# AST1080 register map
File version: 1.0
CPU: CM4 r0p1, little endian, MPU, FPU, 4 interrupt priority bits, 256 interrupts
Registers are 32-bit, read-write, reset 0x0 unless marked. A register's access mark holds for its fields unless they carry their own. Offsets are from the block's base; [hi:lo] are bit positions; {n}, {i} and the like mark numbered series.

## wdt
Base 0x74C03000
Same registers: wdt1 0x74C03080, wdt2 0x74C03100, wdt3 0x74C03180, wdt4 0x74C03200, wdt5 0x74C03280, wdt6 0x74C03300, wdt7 0x74C03380
0x00 WDT000 reset 0x14FB180 — WDTn Counter Status Register
  [31:0] CounterSts ro — Counter status
0x04 WDT004 reset 0x14FB180 — WDTn Counter Reload Value Register
  [31:0] CounterReloadValueReg — Counter reload value register
0x08 WDT008 — WDTn Counter Restart Register
  [15:0] RestartReg — Restart register
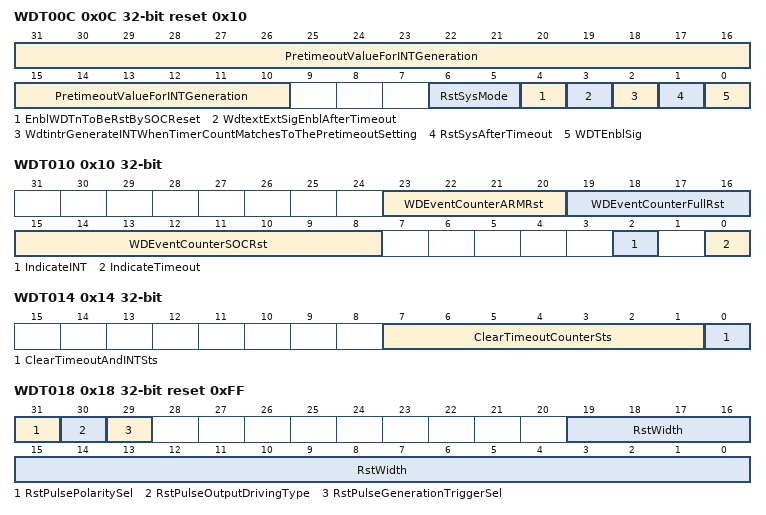
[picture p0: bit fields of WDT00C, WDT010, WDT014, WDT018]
0x0C WDT00C reset 0x10 — WDTn Control Register
  [31:10] PretimeoutValueForINTGeneration — Pre-timeout value for interrupt generation
  [6:5] RstSysMode — Reset system mode
    0=SOC_System_Ewvergated_By_Reset_Mask_Registers; 1=Full_Chip; 0b1x=CPUFMC_Only_Just_Reboot_Firmware_No_Any_Other_IPs_Will_Be_Reset
  [4] EnblWDTnToBeRstBySOCReset — Enable WDT(n) to be reset by SOC reset
    0=WDTn_Can_Not_Be_Reset_By_SOC_Reset_Only_SRST_Or_Full_Chip_Reset_Can_Reset_It; 1=WDTn_Can_Be_Reset_By_SOC_Reset
  [3] WdtextExtSigEnblAfterTimeout — wdt_ext: External signal enable after timeout
    0=Disable; 1=Enable
  [2] WdtintrGenerateINTWhenTimerCountMatchesToThePretimeoutSetting — wdt_intr: Generate interrupt when timer count matches to the pre-timeout setting
    0=Disable; 1=Enable
  [1] RstSysAfterTimeout — Reset system after timeout
    0=Disable; 1=Enable
  [0] WDTEnblSig — WDT enable signal
    0=Disable; 1=Enable
0x10 WDT010 — WDTn Timeout Status Register
  [23:20] WDEventCounterARMRst ro — Watchdog event counter : ARM reset
  [19:16] WDEventCounterFullRst ro — Watchdog event counter : Full reset
  [15:8] WDEventCounterSOCRst ro — Watchdog event counter : SOC reset
  [2] IndicateINT ro — Indicate interrupt
  [0] IndicateTimeout ro
    0=Timeout_Never_Occur; 1=Timeout_Occur
0x14 WDT014 — WDTn Clear Timeout Status Register
  [7:1] ClearTimeoutCounterSts — Clear timeout counter status
  [0] ClearTimeoutAndINTSts — Clear timeout and interrupt status
0x18 WDT018 reset 0xFF — WDTn Reset Width Register
  [31] RstPulsePolaritySel — Reset pulse polarity selection
    0=Active_Low_Output; 1=Active_High_Output
  [30] RstPulseOutputDrivingType — Reset pulse output driving type
    0=Opendrain; 1=Pushpull
  [29] RstPulseGenerationTriggerSel — Reset pulse generation trigger selection
    0=Trigger_By_Timeout; 1=Trigger_By_Pretimeout
  [19:0] RstWidth — Reset width
0x24 WDT024 reset 0x3FFFFF1 (reset mask 0xFF6D01) — WDTn Reset Mask Register \#1
  [n+16] EnblRstI3CBus{n}Ctrl (n=0..7) — Enable reset I3C bus{n} controller
  [14] EnblRstSPI1Ctrl — Enable reset SPI1 controller
  [13] EnblRstSPI0Ctrl — Enable reset SPI0 controller
  [12] EnblRstJTAGMaster1Ctrl — Enable reset JTAG Master #1 controller
  [11] EnblRstJTAGMaster0Ctrl — Enable reset JTAG Master #0 controller
  [11] EnblRstJTAGMasterCtrl — Enable reset JTAG Master controller
  [10] EnblRstESPICtrl — Enable reset eSPI controller
  [10] EnblRstESPICtrl1 — Enable reset eSPI controller
  [8] EnblRstADCCtrl — Enable reset ADC controller
  [4] EnblRstPWMCtrl — Enable reset PWM controller
  [3] EnblRstPECIBridge — Enable reset PECI bridge
  [0] EnblRstLSCRelatedCtrls — Enable reset LSC related controllers
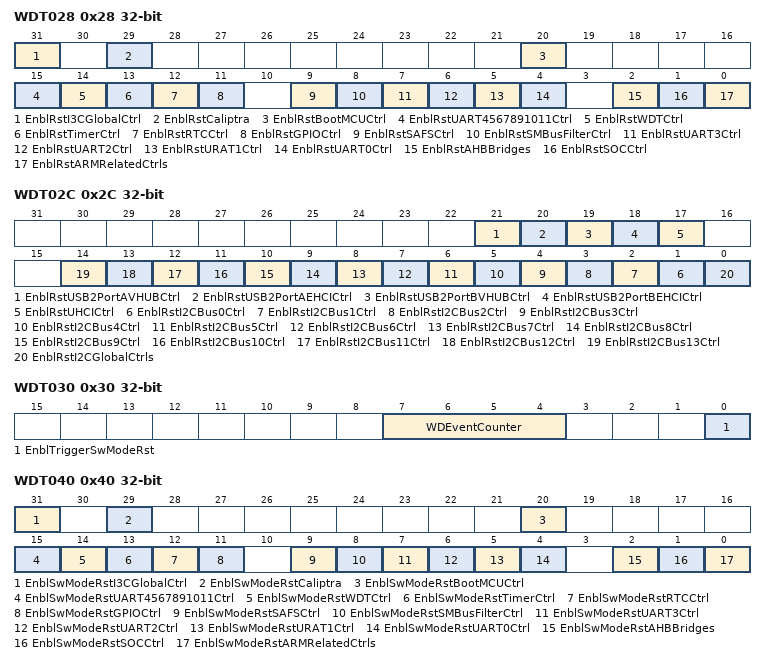
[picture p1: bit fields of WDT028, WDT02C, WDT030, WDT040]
0x28 WDT028 (reset mask 0xA010F8F7) — WDTn Reset Mask Register \#2
  [31] EnblRstI3CGlobalCtrl — Enable reset I3C global controller
  [29] EnblRstCaliptra — Enable reset Caliptra
  [20] EnblRstBootMCUCtrl — Enable reset BootMCU controller
  [15] EnblRstUART4567891011Ctrl — Enable reset UART #4/#5/#6/#7/#8/#9/#10/#11 controller
  [14] EnblRstWDTCtrl — Enable reset WDT controller
  [13] EnblRstTimerCtrl — Enable reset Timer controller
  [12] EnblRstRTCCtrl — Enable reset RTC controller
  [11] EnblRstGPIOCtrl — Enable reset GPIO controller
  [9] EnblRstSAFSCtrl — Enable reset SAFS controller
  [8] EnblRstSMBusFilterCtrl — Enable reset SMBus Filter controller
  [7] EnblRstUART3Ctrl — Enable reset UART #3 controller
  [6] EnblRstUART2Ctrl — Enable reset UART #2 controller
  [5] EnblRstURAT1Ctrl — Enable reset URAT #1 controller
  [4] EnblRstUART0Ctrl — Enable reset UART #0 controller
  [2] EnblRstAHBBridges — Enable reset AHB bridges
  [1] EnblRstSOCCtrl — Enable reset SOC controller
  [0] EnblRstARMRelatedCtrls — Enable reset ARM related controllers
0x2C WDT02C — WDTn Reset Mask Register \#3
  [21] EnblRstUSB2PortAVHUBCtrl — Enable reset USB2 PortA vHUB controller
  [20] EnblRstUSB2PortAEHCICtrl — Enable reset USB2 PortA EHCI controller
  [19] EnblRstUSB2PortBVHUBCtrl — Enable reset USB2 PortB vHUB controller
  [18] EnblRstUSB2PortBEHCICtrl — Enable reset USB2 PortB EHCI controller
  [17] EnblRstUHCICtrl — Enable reset UHCI controller
  [n+1] EnblRstI2CBus{n}Ctrl (n=0..13) — Enable reset I2C bus{n} controller
  [0] EnblRstI2CGlobalCtrls — Enable reset I2C global controllers
0x30 WDT030 — WDTn Software Mode Reset Control Register
  [7:4] WDEventCounter — Watchdog event counter
  [0] EnblTriggerSwModeRst — Enable trigger software mode reset
0x3C WDT03C reset 0x3FFFFF1 (reset mask 0xFF6D01) — WDTn Software Mode Reset Mask Register \#1
  [n+16] EnblSwModeRstI3CBus{n}Ctrl (n=0..7) — Enable Software Mode reset I3C bus{n} controller
  [14] EnblSwModeRstSPI1Ctrl — Enable Software Mode reset SPI1 controller
  [13] EnblSwModeRstSPI0Ctrl — Enable Software Mode reset SPI0 controller
  [12] EnblSwModeRstJTAGMaster1Ctrl — Enable Software Mode reset JTAG Master #1 controller
  [11] EnblSwModeRstJTAGMaster0Ctrl — Enable Software Mode reset JTAG Master #0 controller
  [11] EnblSwModeRstJTAGMasterCtrl — Enable Software Mode reset JTAG Master controller
  [10] EnblSwModeRstESPICtrl — Enable Software Mode reset eSPI controller
  [10] EnblSwModeRstESPICtrl1 — Enable Software Mode reset eSPI controller
  [8] EnblSwModeRstADCCtrl — Enable Software Mode reset ADC controller
  [4] EnblSwModeRstPWMCtrl — Enable Software Mode reset PWM controller
  [3] EnblSwModeRstPECIBridge — Enable Software Mode reset PECI bridge
  [0] EnblSwModeRstLSCRelatedCtrls — Enable Software Mode reset LSC related controllers
0x40 WDT040 (reset mask 0xA010F8F7) — WDTn Software Mode Reset Mask Register \#2
  [31] EnblSwModeRstI3CGlobalCtrl — Enable Software Mode reset I3C global controller
  [29] EnblSwModeRstCaliptra — Enable Software Mode reset Caliptra
  [20] EnblSwModeRstBootMCUCtrl — Enable Software Mode reset BootMCU controller
  [15] EnblSwModeRstUART4567891011Ctrl — Enable Software Mode reset UART #4/#5/#6/#7/#8/#9/#10/#11 controller
  [14] EnblSwModeRstWDTCtrl — Enable Software Mode reset WDT controller
  [13] EnblSwModeRstTimerCtrl — Enable Software Mode reset Timer controller
  [12] EnblSwModeRstRTCCtrl — Enable Software Mode reset RTC controller
  [11] EnblSwModeRstGPIOCtrl — Enable Software Mode reset GPIO controller
  [9] EnblSwModeRstSAFSCtrl — Enable Software Mode reset SAFS controller
  [8] EnblSwModeRstSMBusFilterCtrl — Enable Software Mode reset SMBus Filter controller
  [7] EnblSwModeRstUART3Ctrl — Enable Software Mode reset UART #3 controller
  [6] EnblSwModeRstUART2Ctrl — Enable Software Mode reset UART #2 controller
  [5] EnblSwModeRstURAT1Ctrl — Enable Software Mode reset URAT #1 controller
  [4] EnblSwModeRstUART0Ctrl — Enable Software Mode reset UART #0 controller
  [2] EnblSwModeRstAHBBridges — Enable Software Mode reset AHB bridges
  [1] EnblSwModeRstSOCCtrl — Enable Software Mode reset SOC controller
  [0] EnblSwModeRstARMRelatedCtrls — Enable Software Mode reset ARM related controllers
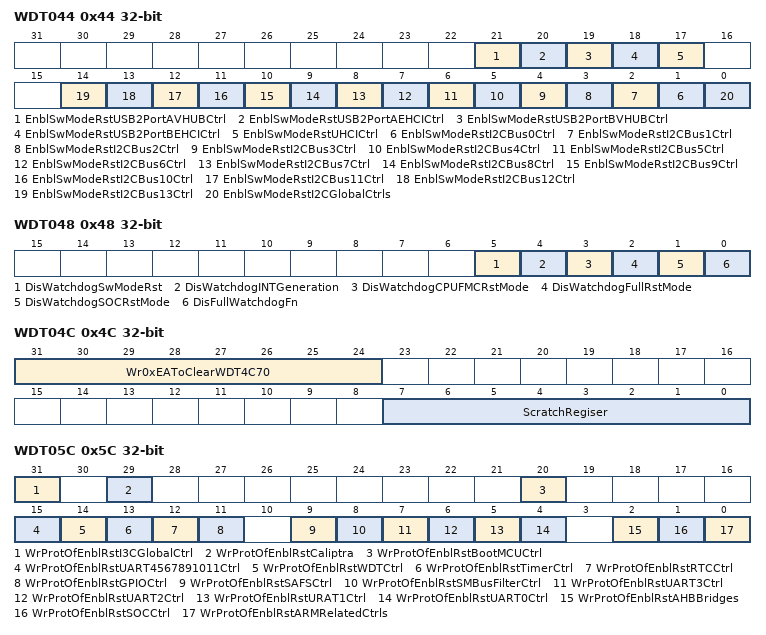
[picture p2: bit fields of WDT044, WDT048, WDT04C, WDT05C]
0x44 WDT044 — WDTn Software Mode Reset Mask Register \#3
  [21] EnblSwModeRstUSB2PortAVHUBCtrl — Enable Software Mode reset USB2 PortA vHUB controller
  [20] EnblSwModeRstUSB2PortAEHCICtrl — Enable Software Mode reset USB2 PortA EHCI controller
  [19] EnblSwModeRstUSB2PortBVHUBCtrl — Enable Software Mode reset USB2 PortB vHUB controller
  [18] EnblSwModeRstUSB2PortBEHCICtrl — Enable Software Mode reset USB2 PortB EHCI controller
  [17] EnblSwModeRstUHCICtrl — Enable Software Mode reset UHCI controller
  [n+1] EnblSwModeRstI2CBus{n}Ctrl (n=0..13) — Enable Software Mode reset I2C bus{n} controller
  [0] EnblSwModeRstI2CGlobalCtrls — Enable Software Mode reset I2C global controllers
0x48 WDT048 — WDTn Funtion Disable Control Register
  [5] DisWatchdogSwModeRst — Disable watchdog Software mode reset
  [4] DisWatchdogINTGeneration — Disable watchdog interrupt generation
  [3] DisWatchdogCPUFMCRstMode — Disable watchdog CPU/FMC reset mode
  [2] DisWatchdogFullRstMode — Disable watchdog Full reset mode
  [1] DisWatchdogSOCRstMode — Disable watchdog SOC reset mode
  [0] DisFullWatchdogFn — Disable full watchdog function
0x4C WDT04C — WDTn Scratch Register
  [31:24] Wr0xEAToClearWDT4C70 — Write 0xEA to clear WDT4C[7:0]
  [7:0] ScratchRegiser
0x58 WDT058 reset 0x3FFFFF1 (reset mask 0xFF6D01) — WDTn Reset Mask Write Protection Register \#1
  [n+16] WrProtOfEnblRstI3CBus{n}Ctrl (n=0..7) — Write Protection of Enable reset I3C bus{n} controller
  [14] WrProtOfEnblRstSPI1Ctrl — Write Protection of Enable reset SPI1 controller
  [13] WrProtOfEnblRstSPI0Ctrl — Write Protection of Enable reset SPI0 controller
  [12] WrProtOfEnblRstJTAGMaster1Ctrl — Write Protection of Enable reset JTAG Master #1 controller
  [11] WrProtOfEnblRstJTAGMaster0Ctrl — Write Protection of Enable reset JTAG Master #0 controller
  [11] WrProtOfEnblRstJTAGMasterCtrl — Write Protection of Enable reset JTAG Master controller
  [10] WrProtOfEnblRstESPICtrl — Write Protection of Enable reset eSPI controller
  [10] WrProtOfEnblRstESPICtrl1 — Write Protection of Enable reset eSPI controller
  [8] WrProtOfEnblRstADCCtrl — Write Protection of Enable reset ADC controller
  [4] WrProtOfEnblRstPWMCtrl — Write Protection of Enable reset PWM controller
  [3] WrProtOfEnblRstPECIBridge — Write Protection of Enable reset PECI bridge
  [0] WrProtOfEnblRstLSCRelatedCtrls — Write Protection of Enable reset LSC related controllers
0x5C WDT05C (reset mask 0xA010F8F7) — WDTn Reset Mask Write Protection Register \#2
  [31] WrProtOfEnblRstI3CGlobalCtrl — Write Protection of Enable reset I3C global controller
  [29] WrProtOfEnblRstCaliptra — Write Protection of Enable reset Caliptra
  [20] WrProtOfEnblRstBootMCUCtrl — Write Protection of Enable reset BootMCU controller
  [15] WrProtOfEnblRstUART4567891011Ctrl — Write Protection of Enable reset UART #4/#5/#6/#7/#8/#9/#10/#11 controller
  [14] WrProtOfEnblRstWDTCtrl — Write Protection of Enable reset WDT controller
  [13] WrProtOfEnblRstTimerCtrl — Write Protection of Enable reset Timer controller
  [12] WrProtOfEnblRstRTCCtrl — Write Protection of Enable reset RTC controller
  [11] WrProtOfEnblRstGPIOCtrl — Write Protection of Enable reset GPIO controller
  [9] WrProtOfEnblRstSAFSCtrl — Write Protection of Enable reset SAFS controller
  [8] WrProtOfEnblRstSMBusFilterCtrl — Write Protection of Enable reset SMBus Filter controller
  [7] WrProtOfEnblRstUART3Ctrl — Write Protection of Enable reset UART #3 controller
  [6] WrProtOfEnblRstUART2Ctrl — Write Protection of Enable reset UART #2 controller
  [5] WrProtOfEnblRstURAT1Ctrl — Write Protection of Enable reset URAT #1 controller
  [4] WrProtOfEnblRstUART0Ctrl — Write Protection of Enable reset UART #0 controller
  [2] WrProtOfEnblRstAHBBridges — Write Protection of Enable reset AHB bridges
  [1] WrProtOfEnblRstSOCCtrl — Write Protection of Enable reset SOC controller
  [0] WrProtOfEnblRstARMRelatedCtrls — Write Protection of Enable reset ARM related controllers
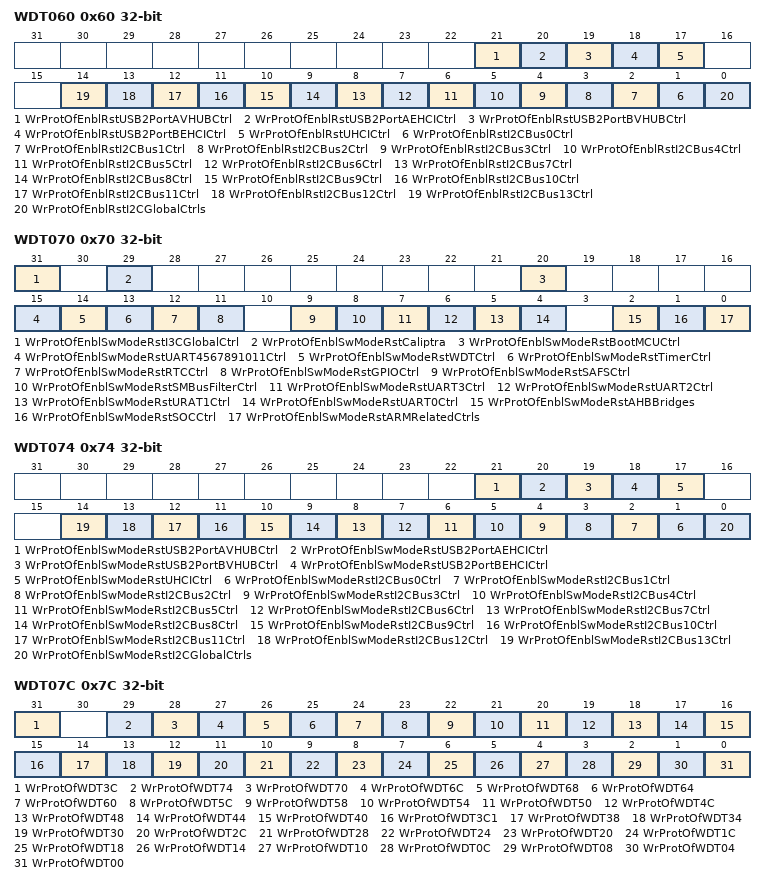
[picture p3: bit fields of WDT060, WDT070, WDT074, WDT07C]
0x60 WDT060 — WDTn Reset Mask Write Protection Register \#3
  [21] WrProtOfEnblRstUSB2PortAVHUBCtrl — Write Protection of Enable reset USB2 PortA vHUB controller
  [20] WrProtOfEnblRstUSB2PortAEHCICtrl — Write Protection of Enable reset USB2 PortA EHCI controller
  [19] WrProtOfEnblRstUSB2PortBVHUBCtrl — Write Protection of Enable reset USB2 PortB vHUB controller
  [18] WrProtOfEnblRstUSB2PortBEHCICtrl — Write Protection of Enable reset USB2 PortB EHCI controller
  [17] WrProtOfEnblRstUHCICtrl — Write Protection of Enable reset UHCI controller
  [n+1] WrProtOfEnblRstI2CBus{n}Ctrl (n=0..13) — Write Protection of Enable reset I2C bus{n} controller
  [0] WrProtOfEnblRstI2CGlobalCtrls — Write Protection of Enable reset I2C global controllers
0x6C WDT06C reset 0x3FFFFF1 (reset mask 0xFF6D01) — WDTn Reset Mask Write Protection Register \#1
  [n+16] WrProtOfEnblSwModeRstI3CBus{n}Ctrl (n=0..7) — Write Protection of Enable Software Mode reset I3C bus{n} controller
  [14] WrProtOfEnblSwModeRstSPI1Ctrl — Write Protection of Enable Software Mode reset SPI1 controller
  [13] WrProtOfEnblSwModeRstSPI0Ctrl — Write Protection of Enable Software Mode reset SPI0 controller
  [12] WrProtOfEnblSwModeRstJTAGMaster1Ctrl — Write Protection of Enable Software Mode reset JTAG Master #1 controller
  [11] WrProtOfEnblSwModeRstJTAGMaster0Ctrl — Write Protection of Enable Software Mode reset JTAG Master #0 controller
  [11] WrProtOfEnblSwModeRstJTAGMasterCtrl — Write Protection of Enable Software Mode reset JTAG Master controller
  [10] WrProtOfEnblSwModeRstESPICtrl — Write Protection of Enable Software Mode reset eSPI controller
  [10] WrProtOfEnblSwModeRstESPICtrl1 — Write Protection of Enable Software Mode reset eSPI controller
  [8] WrProtOfEnblSwModeRstADCCtrl — Write Protection of Enable Software Mode reset ADC controller
  [4] WrProtOfEnblSwModeRstPWMCtrl — Write Protection of Enable Software Mode reset PWM controller
  [3] WrProtOfEnblSwModeRstPECIBridge — Write Protection of Enable Software Mode reset PECI bridge
  [0] WrProtOfEnblSwModeRstLSCRelatedCtrls — Write Protection of Enable Software Mode reset LSC related controllers
0x70 WDT070 (reset mask 0xA010F8F7) — WDTn Reset Mask Write Protection Register \#2
  [31] WrProtOfEnblSwModeRstI3CGlobalCtrl — Write Protection of Enable Software Mode reset I3C global controller
  [29] WrProtOfEnblSwModeRstCaliptra — Write Protection of Enable Software Mode reset Caliptra
  [20] WrProtOfEnblSwModeRstBootMCUCtrl — Write Protection of Enable Software Mode reset BootMCU controller
  [15] WrProtOfEnblSwModeRstUART4567891011Ctrl — Write Protection of Enable Software Mode reset UART #4/#5/#6/#7/#8/#9/#10/#11 controller
  [14] WrProtOfEnblSwModeRstWDTCtrl — Write Protection of Enable Software Mode reset WDT controller
  [13] WrProtOfEnblSwModeRstTimerCtrl — Write Protection of Enable Software Mode reset Timer controller
  [12] WrProtOfEnblSwModeRstRTCCtrl — Write Protection of Enable Software Mode reset RTC controller
  [11] WrProtOfEnblSwModeRstGPIOCtrl — Write Protection of Enable Software Mode reset GPIO controller
  [9] WrProtOfEnblSwModeRstSAFSCtrl — Write Protection of Enable Software Mode reset SAFS controller
  [8] WrProtOfEnblSwModeRstSMBusFilterCtrl — Write Protection of Enable Software Mode reset SMBus Filter controller
  [7] WrProtOfEnblSwModeRstUART3Ctrl — Write Protection of Enable Software Mode reset UART #3 controller
  [6] WrProtOfEnblSwModeRstUART2Ctrl — Write Protection of Enable Software Mode reset UART #2 controller
  [5] WrProtOfEnblSwModeRstURAT1Ctrl — Write Protection of Enable Software Mode reset URAT #1 controller
  [4] WrProtOfEnblSwModeRstUART0Ctrl — Write Protection of Enable Software Mode reset UART #0 controller
  [2] WrProtOfEnblSwModeRstAHBBridges — Write Protection of Enable Software Mode reset AHB bridges
  [1] WrProtOfEnblSwModeRstSOCCtrl — Write Protection of Enable Software Mode reset SOC controller
  [0] WrProtOfEnblSwModeRstARMRelatedCtrls — Write Protection of Enable Software Mode reset ARM related controllers
0x74 WDT074 — WDTn Reset Mask Write Protection Register \#3
  [21] WrProtOfEnblSwModeRstUSB2PortAVHUBCtrl — Write Protection of Enable Software Mode reset USB2 PortA vHUB controller
  [20] WrProtOfEnblSwModeRstUSB2PortAEHCICtrl — Write Protection of Enable Software Mode reset USB2 PortA EHCI controller
  [19] WrProtOfEnblSwModeRstUSB2PortBVHUBCtrl — Write Protection of Enable Software Mode reset USB2 PortB vHUB controller
  [18] WrProtOfEnblSwModeRstUSB2PortBEHCICtrl — Write Protection of Enable Software Mode reset USB2 PortB EHCI controller
  [17] WrProtOfEnblSwModeRstUHCICtrl — Write Protection of Enable Software Mode reset UHCI controller
  [n+1] WrProtOfEnblSwModeRstI2CBus{n}Ctrl (n=0..13) — Write Protection of Enable Software Mode reset I2C bus{n} controller
  [0] WrProtOfEnblSwModeRstI2CGlobalCtrls — Write Protection of Enable Software Mode reset I2C global controllers
0x7C WDT07C — WDTn Write Protection Register
  [31] WrProtOfWDT3C — Write Protection of WDT3C
  [29] WrProtOfWDT74 — Write Protection of WDT74
  [28] WrProtOfWDT70 — Write Protection of WDT70
  [27] WrProtOfWDT6C — Write Protection of WDT6C
  [26] WrProtOfWDT68 — Write Protection of WDT68
  [25] WrProtOfWDT64 — Write Protection of WDT64
  [24] WrProtOfWDT60 — Write Protection of WDT60
  [23] WrProtOfWDT5C — Write Protection of WDT5C
  [22] WrProtOfWDT58 — Write Protection of WDT58
  [21] WrProtOfWDT54 — Write Protection of WDT54
  [20] WrProtOfWDT50 — Write Protection of WDT50
  [19] WrProtOfWDT4C — Write Protection of WDT4C
  [18] WrProtOfWDT48 — Write Protection of WDT48
  [17] WrProtOfWDT44 — Write Protection of WDT44
  [16] WrProtOfWDT40 — Write Protection of WDT40
  [15] WrProtOfWDT3C1 — Write Protection of WDT3C
  [14] WrProtOfWDT38 — Write Protection of WDT38
  [13] WrProtOfWDT34 — Write Protection of WDT34
  [12] WrProtOfWDT30 — Write Protection of WDT30
  [11] WrProtOfWDT2C — Write Protection of WDT2C
  [10] WrProtOfWDT28 — Write Protection of WDT28
  [9] WrProtOfWDT24 — Write Protection of WDT24
  [8] WrProtOfWDT20 — Write Protection of WDT20
  [7] WrProtOfWDT1C — Write Protection of WDT1C
  [6] WrProtOfWDT18 — Write Protection of WDT18
  [5] WrProtOfWDT14 — Write Protection of WDT14
  [4] WrProtOfWDT10 — Write Protection of WDT10
  [3] WrProtOfWDT0C — Write Protection of WDT0C
  [2] WrProtOfWDT08 — Write Protection of WDT08
  [1] WrProtOfWDT04 — Write Protection of WDT04
  [0] WrProtOfWDT00 — Write Protection of WDT00
